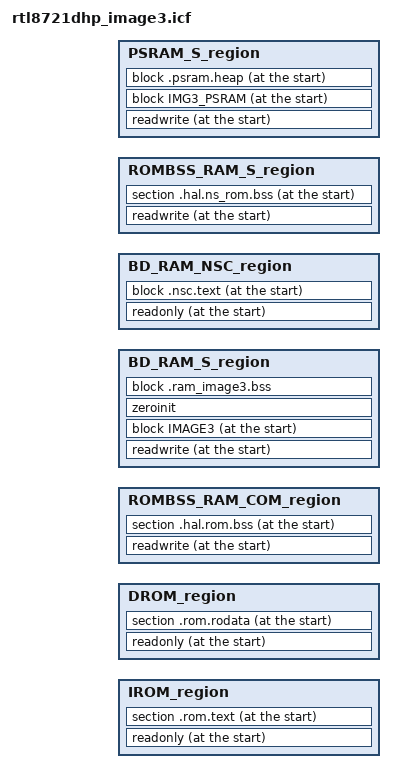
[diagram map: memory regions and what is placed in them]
/*###ICF### Section handled by ICF editor, don't touch! ****/
/*-Editor annotation file-*/
/* IcfEditorFile="$TOOLKIT_DIR$\config\ide\IcfEditor\cortex_v1_0.xml" */
/*-Specials-*/

include "rtl8721dhp_rom_symbol_s.icf";
include "rtl8721d_memory_layout_tz.icf";

/*-Sizes-*/
/*define symbol __ICFEDIT_size_cstack__   = 0x400;*/
/*define symbol __ICFEDIT_size_heap__     = 0x800;*/
/**** End of ICF editor section. ###ICF###*/

define memory mem with size = 4G;
define region IROM_region   		= mem:[from __ICFEDIT_region_HS_IROM_start__   to __ICFEDIT_region_HS_IROM_end__];
define region IROM_NS_region   		= mem:[from __ICFEDIT_region_HS_IROM_NS_start__   to __ICFEDIT_region_HS_IROM_NS_end__];
define region DROM_NS_region   		= mem:[from __ICFEDIT_region_HS_DROM_NS_start__   to __ICFEDIT_region_HS_DROM_NS_end__];
define region DROM_region  		= mem:[from __ICFEDIT_region_HS_DROM_start__   to __ICFEDIT_region_HS_DROM_end__];
define region ROMBSS_RAM_COM_region   	= mem:[from __ICFEDIT_region_HS_ROMBSS_RAM_COM_start__   to __ICFEDIT_region_HS_ROMBSS_RAM_COM_end__];
define region ROMBSS_RAM_NS_region   	= mem:[from __ICFEDIT_region_HS_ROMBSS_RAM_NS_start__   to __ICFEDIT_region_HS_ROMBSS_RAM_NS_end__];
define region RSVD_RAM_NS_region   	= mem:[from __ICFEDIT_region_HS_RSVD_RAM_NS_start__   to __ICFEDIT_region_HS_RSVD_RAM_NS_end__];
define region MSP_RAM_NS_region   	= mem:[from __ICFEDIT_region_HS_MSP_RAM_NS_start__   to __ICFEDIT_region_HS_MSP_RAM_NS_end__];
define region BD_RAM_NS_region   	= mem:[from __ICFEDIT_region_HS_BD_RAM_NS_start__   to __ICFEDIT_region_HS_BD_RAM_NS_end__];
define region BD_RAM_S_region   	= mem:[from __ICFEDIT_region_HS_BD_RAM_S_start__   to __ICFEDIT_region_HS_BD_RAM_S_end__];
define region BD_RAM_NSC_region   	= mem:[from __ICFEDIT_region_HS_BD_RAM_NSC_start__   to __ICFEDIT_region_HS_BD_RAM_NSC_end__];
define region ROMBSS_RAM_S_region   	= mem:[from __ICFEDIT_region_HS_ROMBSS_RAM_S_start__   to __ICFEDIT_region_HS_ROMBSS_RAM_S_end__];
define region BOOTLOADER_RAM_S_region   = mem:[from __ICFEDIT_region_HS_BOOTLOADER_RAM_S_start__   to __ICFEDIT_region_HS_BOOTLOADER_RAM_S_end__];
define region MSP_RAM_S_region   	= mem:[from __ICFEDIT_region_HS_MSP_RAM_S_start__   to __ICFEDIT_region_HS_MSP_RAM_S_end__];
define region EXTENTION_SRAM_region   	= mem:[from __ICFEDIT_region_HS_EXTENTION_SRAM_start__   to __ICFEDIT_region_HS_EXTENTION_SRAM_end__];
define region PSRAM_S_region   		= mem:[from __ICFEDIT_region_HS_PSRAM_S_start__   to __ICFEDIT_region_HS_PSRAM_S_end__];
define region KM4_BOOT_region   	= mem:[from __ICFEDIT_region_HS_FLASH_BOOT_start__   to __ICFEDIT_region_HS_FLASH_BOOT_end__];
define region KM4_IMG2_region   	= mem:[from __ICFEDIT_region_HS_FLASH_IMG2_start__   to __ICFEDIT_region_HS_FLASH_IMG2_end__];
define region BTRACE_region   		= mem:[from __ICFEDIT_region_HS_BTRACE_start__   to __ICFEDIT_region_HS_BTRACE_end__];
define region RETENTION_RAM_region   	= mem:[from __ICFEDIT_region_RETENTION_RAM_start__   to __ICFEDIT_region_RETENTION_RAM_end__];


/*define block CSTACK    with alignment = 8, size = __ICFEDIT_size_cstack__   { };*/
/*define block HEAP      with alignment = 8, size = __ICFEDIT_size_heap__     { };*/

//initialize by copy { readwrite };
//initialize by copy with packing = none { section __DLIB_PERTHREAD }; // Required in a multi-threaded application

//do not initialize  { section * };
do not initialize { readwrite };

/****************************************
 * ROM Section config                   *
 ****************************************/
keep { section .rom.text };
place at start of IROM_region   { readonly, section .rom.text };

keep { section .rom.rodata };
place at start of DROM_region   { readonly, section .rom.rodata };

/****************************************
 * ROM BSS Section config                *
 ****************************************/
keep { section .hal.rom.bss };
place at start of ROMBSS_RAM_COM_region  { readwrite, section .hal.rom.bss };

keep { section .hal.s_rom.bss };
place at start of ROMBSS_RAM_S_region  { readwrite, section .hal.ns_rom.bss };

/****************************************
 * BD RAM NSC Section config                *
 ****************************************/
define block .nsc.text with alignment = 16 { section Veneer$$CMSE };
place at start of BD_RAM_NSC_region   { readonly, block .nsc.text};

keep { section .image3.nsc_entry.text* };
define block .ram_image3.text with fixed order{ section .image3.nsc_entry.text*, 
                                                section .text*,
                                                section .rodata*,
                                              };

define block SHT$$PREINIT_ARRAY { preinit_array };
define block SHT$$INIT_ARRAY { init_array };
define block CPP_INIT with fixed order { block SHT$$PREINIT_ARRAY,
					block SHT$$INIT_ARRAY };

define block .ram_image3.data with fixed order{ section .data*,
						section DATA, 
						section .iar.init_table,
						section __DLIB_PERTHREAD,
                                                block CPP_INIT,
                                              };

define block IMAGE3 with fixed order { block .ram_image3.text,
                                       block .ram_image3.data,
                                     };

keep { section .bss* };
define block .ram_image3.bss with alignment = 16 { section .bss*,
						section .ssl_ram_map,
                                                section COMMON,
                                              };

place at start of BD_RAM_S_region {readwrite, block IMAGE3};

place in BD_RAM_S_region {zeroinit,  block .ram_image3.bss};

/****************************************
 * PSRAM Section config                *
 ****************************************/
define block IMG3_PSRAM with fixed order { 	section .psram.text,
						section .psram.data,
					 	section .psram.rodata };

define block .psram.heap with alignment = 16 { 	section .psram.bss,
						section .psram.heap };

keep { block IMG3_PSRAM };

place at start of PSRAM_S_region   {  readwrite,
					block IMG3_PSRAM,
					block .psram.heap,
				 };

define exported symbol __psram_image3_text_start__ = __ICFEDIT_region_HS_PSRAM_S_start__; 

